# F28x7x_sdfm_regs register map
Vendor: Texas Instruments
Peripheral module from a debugger description file (folder C2000).
Address unit: 16 bits
Registers are 16-bit, read-write, no defined reset value unless marked. A register's access mark holds for its fields unless they carry their own. Offsets are as the file gives them; lines under a group give offsets from that group; [hi:lo] are bit positions; {n}, {i} and the like mark numbered series; 'fields as' and 'values as' point back to an identical list; <NAME> marks a mode.

## SDFM_REGS
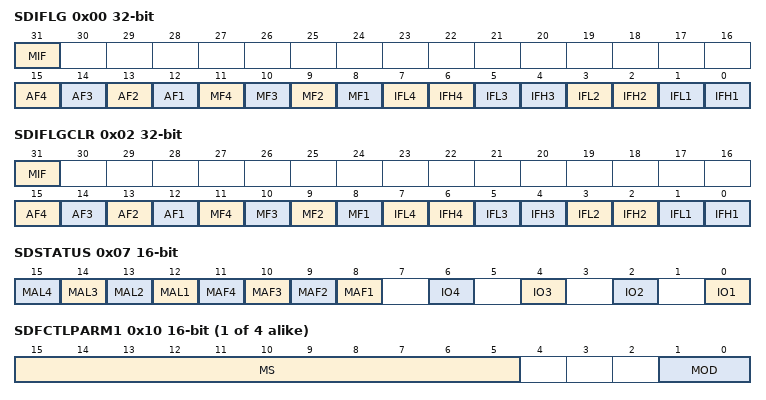
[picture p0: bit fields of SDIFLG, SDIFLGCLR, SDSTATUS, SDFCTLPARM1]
0x00 SDIFLG 32-bit — Interrupt Flag Register
  [31] MIF — Master Interrupt Flag
  [n+11] AF{n} (n=1..4) — Acknowledge flag for Filter {n}
  [n+7] MF{n} (n=1..4) — Modulator Failure for Filter {n}
  [2n-1] IFL{n} (n=1..4) — Low-Level Interrupt flag Filter {n}
  [2n-2] IFH{n} (n=1..4) — High-level Interrupt flag Filter {n}
0x02 SDIFLGCLR 32-bit — Interrupt Flag Clear Register
  fields as SDIFLG
0x04 SDCTL — SD Control Register
  [13] MIE — Master Interrupt enable
0x06 SDMFILEN — SD Master Filter Enable
  [11] MFE — Master Filter Enable.
0x07 SDSTATUS
  [n+11] MAL{n} (n=1..4) — Manchester locked status for filter module {n}.
  [n+7] MAF{n} (n=1..4) — Manchester failure status for filter module {n}.
  [2n-2] IO{n} (n=1..4) — Integrator overflow for filter module {n}.
{0x0+0x10*i} SDFCTLPARM{i} (i=1..4) — Control Parameter Register for Ch{i}
  [15:5] MS — Manchester Status
  [1:0] MOD — Delta-Sigma Modulator mode
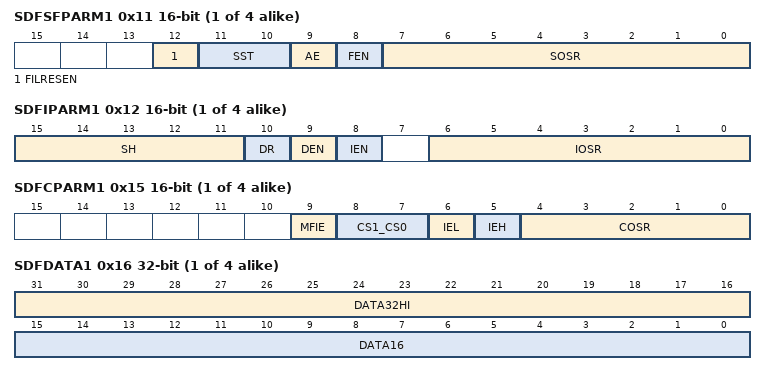
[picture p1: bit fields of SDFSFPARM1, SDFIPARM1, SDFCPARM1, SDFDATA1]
{0x1+0x10*i} SDFSFPARM{i} (i=1..4) — Sinc Filter Parameter Register for Ch{i}
  [12] FILRESEN — SINC FILTER Reset Enable
  [11:10] SST — SINC Filter Structure (SincFast/1/2/3)
  [9] AE — Ack Enable
  [8] FEN — Filter Enable
  [7:0] SOSR — SINC Filter Oversample Ratio= SOSR+1
{0x2+0x10*i} SDFIPARM{i} (i=1..4) — Integrator Parameter Register for Ch{i}
  [15:11] SH — Shift Control (# bits to shift in 16b mode)
  [10] DR — Data Representation (0/1 = 16/32b 2's complement)
  [9] DEN — Demodulation enable (for Resolver apps)
  [8] IEN — Integrator enable
  [6:0] IOSR — Integrator Oversample Ratio= IOSR+1
{0x3+0x10*i} SDFCMPH{i} (i=1..4) — High-level Threshold Register for Ch{i}
  [14:0] HLT — High-level threshold for the comparator filter output.
{0x4+0x10*i} SDFCMPL{i} (i=1..4) — Low-level Threshold Register for Ch{i}
  [14:0] LLT — Low-level threshold for the comparator filter output.
{0x5+0x10*i} SDFCPARM{i} (i=1..4) — Comparator Parameter Register for Ch{i}
  [9] MFIE — Modulator Failure Interrupt enable
  [8:7] CS1_CS0 — Comparator filter structure (Sincfast/Sinc1/Sinc2/Sinc3
  [6] IEL — Low-level interrupt enable
  [5] IEH — High-level interrupt enable
  [4:0] COSR — Comparator Oversample Ratio = COSR + 1
{0x6+0x10*i} SDFDATA{i} 32-bit (i=1..4) — Filter Data Register (16 or 32bit) for Ch{i}
  [31:16] DATA32HI — Hi-order 16b in 32b mode
  [15:0] DATA16 — 16-bit Data in 16b mode, Lo-order 16b in 32b mode
